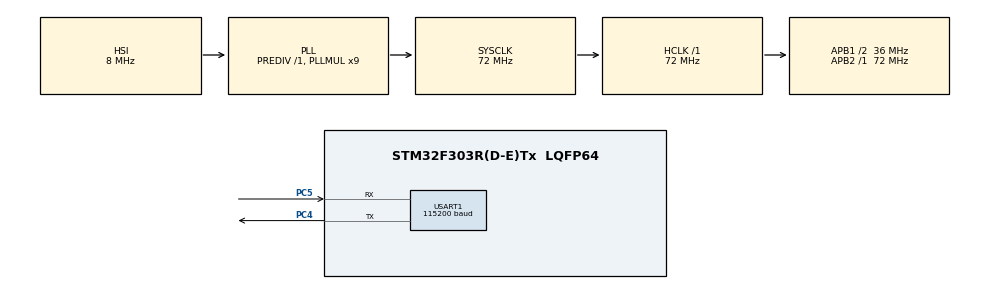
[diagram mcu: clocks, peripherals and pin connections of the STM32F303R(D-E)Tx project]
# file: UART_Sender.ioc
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Mcu.Family=STM32F3
PA2.GPIO_PuPd=GPIO_NOPULL
RCC.CortexFreq_Value=72000000
USART1.BaudRate=115200
RCC.SYSCLKSourceVirtual=RCC_SYSCLKSOURCE_PLLCLK
PA3.GPIO_PuPd=GPIO_NOPULL
PC4.Signal=USART1_TX
PA2.GPIO_Speed=GPIO_SPEED_FREQ_LOW
PC5.Mode=Asynchronous
RCC.APB1CLKDivider=RCC_HCLK_DIV2
PA3.GPIO_Speed=GPIO_SPEED_FREQ_LOW
ProjectManager.StackSize=0x400
USART1.VirtualMode-Asynchronous=VM_ASYNC
ProjectManager.TargetToolchain=STM32CubeIDE
PA3.GPIO_Mode=GPIO_MODE_AF_PP
RCC.HCLKFreq_Value=72000000
RCC.APB2TimFreq_Value=72000000
RCC.USBFreq_Value=72000000
RCC.LSE_VALUE=32768
RCC.AHBFreq_Value=72000000
RCC.HSE_VALUE=8000000
board=NUCLEO-F303RE
RCC.RCC_PLLsource_Clock_Source_FROM_HSE=RCC_HSE_PREDIV_DIV2
RCC.PLLMUL=RCC_PLL_MUL9
RCC.APB2Freq_Value=72000000
USART1.Mode=MODE_TX
Mcu.Name=STM32F303R(D-E)Tx
PA2.Signal=USART2_TX
RCC.SYSCLKFreq_VALUE=72000000
Mcu.Package=LQFP64
PA2.GPIO_Label=USART_TX
ProjectManager.HeapSize=0x200
RCC.HSI_VALUE=8000000
RCC.PLLP=RCC_PLLP_DIV4
RCC.PLLQ=7
NVIC.PriorityGroup=NVIC_PRIORITYGROUP_0
RCC.PLLM=8
RCC.PLLN=336
RCC.APB1TimFreq_Value=72000000
PC5.Signal=USART1_RX
RCC.APB1Freq_Value=36000000
PC4.Mode=Asynchronous
PA3.GPIO_Label=USART_RX
PA3.Signal=USART2_RX
PA2.GPIO_Mode=GPIO_MODE_AF_PP

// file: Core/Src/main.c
/* USER CODE BEGIN Header */
/**
  ******************************************************************************
  * @file           : main.c
  * @brief          : Main program body
  ******************************************************************************
  * @attention
  *
  * <h2><center>&copy; Copyright (c) 2021 STMicroelectronics.
  * All rights reserved.</center></h2>
  *
  * This software component is licensed by ST under BSD 3-Clause license,
  * the "License"; You may not use this file except in compliance with the
  * License. You may obtain a copy of the License at:
  *                        opensource.org/licenses/BSD-3-Clause
  *
  ******************************************************************************
  */
/* USER CODE END Header */
#include "main.h"

UART_HandleTypeDef huart1;

void SystemClock_Config(void);
static void MX_GPIO_Init(void);
static void MX_USART1_UART_Init(void);

/* USER CODE BEGIN 0 */
uint8_t buff[2] = { 0 };
int speed = 0, distance = 0;
/* USER CODE END 0 */

int main(void)
{

  /* MCU Configuration--------------------------------------------------------*/

  /* Reset of all peripherals, Initializes the Flash interface and the Systick. */
  HAL_Init();

  /* Configure the system clock */
  SystemClock_Config();

  /* Initialize all configured peripherals */
  MX_GPIO_Init();
  MX_USART1_UART_Init();

  /* Infinite loop */
  while (1)
  {

    /* USER CODE BEGIN 3 */

	  if (speed > 140)
	  {
		  speed = 0;
	  }

	  if (distance > 20)
	  {
		  distance = 0;
	  }

	  buff[0] = speed;
	  buff[1] = distance;

	  HAL_UART_Transmit(&huart1, buff, sizeof(buff) / sizeof(buff[0]), 10);
	  HAL_Delay(50);

	  speed += 3;
	  distance += 1;
  }
  /* USER CODE END 3 */
}

void SystemClock_Config(void)
{
  RCC_OscInitTypeDef RCC_OscInitStruct = {0};
  RCC_ClkInitTypeDef RCC_ClkInitStruct = {0};
  RCC_PeriphCLKInitTypeDef PeriphClkInit = {0};

  /** Initializes the RCC Oscillators according to the specified parameters
  * in the RCC_OscInitTypeDef structure.
  */
  RCC_OscInitStruct.OscillatorType = RCC_OSCILLATORTYPE_HSI;
  RCC_OscInitStruct.HSIState = RCC_HSI_ON;
  RCC_OscInitStruct.HSICalibrationValue = RCC_HSICALIBRATION_DEFAULT;
  RCC_OscInitStruct.PLL.PLLState = RCC_PLL_ON;
  RCC_OscInitStruct.PLL.PLLSource = RCC_PLLSOURCE_HSI;
  RCC_OscInitStruct.PLL.PLLMUL = RCC_PLL_MUL9;
  RCC_OscInitStruct.PLL.PREDIV = RCC_PREDIV_DIV1;
  if (HAL_RCC_OscConfig(&RCC_OscInitStruct) != HAL_OK)
  {
    Error_Handler();
  }
  /** Initializes the CPU, AHB and APB buses clocks
  */
  RCC_ClkInitStruct.ClockType = RCC_CLOCKTYPE_HCLK|RCC_CLOCKTYPE_SYSCLK
                              |RCC_CLOCKTYPE_PCLK1|RCC_CLOCKTYPE_PCLK2;
  RCC_ClkInitStruct.SYSCLKSource = RCC_SYSCLKSOURCE_PLLCLK;
  RCC_ClkInitStruct.AHBCLKDivider = RCC_SYSCLK_DIV1;
  RCC_ClkInitStruct.APB1CLKDivider = RCC_HCLK_DIV2;
  RCC_ClkInitStruct.APB2CLKDivider = RCC_HCLK_DIV1;

  if (HAL_RCC_ClockConfig(&RCC_ClkInitStruct, FLASH_LATENCY_2) != HAL_OK)
  {
    Error_Handler();
  }
  PeriphClkInit.PeriphClockSelection = RCC_PERIPHCLK_USART1;
  PeriphClkInit.Usart1ClockSelection = RCC_USART1CLKSOURCE_PCLK2;
  if (HAL_RCCEx_PeriphCLKConfig(&PeriphClkInit) != HAL_OK)
  {
    Error_Handler();
  }
}

static void MX_USART1_UART_Init(void)
{

  huart1.Instance = USART1;
  huart1.Init.BaudRate = 115200;
  huart1.Init.WordLength = UART_WORDLENGTH_8B;
  huart1.Init.StopBits = UART_STOPBITS_1;
  huart1.Init.Parity = UART_PARITY_NONE;
  huart1.Init.Mode = UART_MODE_TX;
  huart1.Init.HwFlowCtl = UART_HWCONTROL_NONE;
  huart1.Init.OverSampling = UART_OVERSAMPLING_16;
  huart1.Init.OneBitSampling = UART_ONE_BIT_SAMPLE_DISABLE;
  huart1.AdvancedInit.AdvFeatureInit = UART_ADVFEATURE_NO_INIT;
  if (HAL_UART_Init(&huart1) != HAL_OK)
  {
    Error_Handler();
  }

}

static void MX_GPIO_Init(void)
{
  GPIO_InitTypeDef GPIO_InitStruct = {0};

  /* GPIO Ports Clock Enable */
  __HAL_RCC_GPIOA_CLK_ENABLE();
  __HAL_RCC_GPIOC_CLK_ENABLE();

  /*Configure GPIO pins : USART_TX_Pin USART_RX_Pin */
  GPIO_InitStruct.Pin = USART_TX_Pin|USART_RX_Pin;
  GPIO_InitStruct.Mode = GPIO_MODE_AF_PP;
  GPIO_InitStruct.Pull = GPIO_NOPULL;
  GPIO_InitStruct.Speed = GPIO_SPEED_FREQ_LOW;
  GPIO_InitStruct.Alternate = GPIO_AF7_USART2;
  HAL_GPIO_Init(GPIOA, &GPIO_InitStruct);

}

void Error_Handler(void)
{
  __disable_irq();
  while (1)
  {
  }
}

/************************ (C) COPYRIGHT STMicroelectronics *****END OF FILE****/
